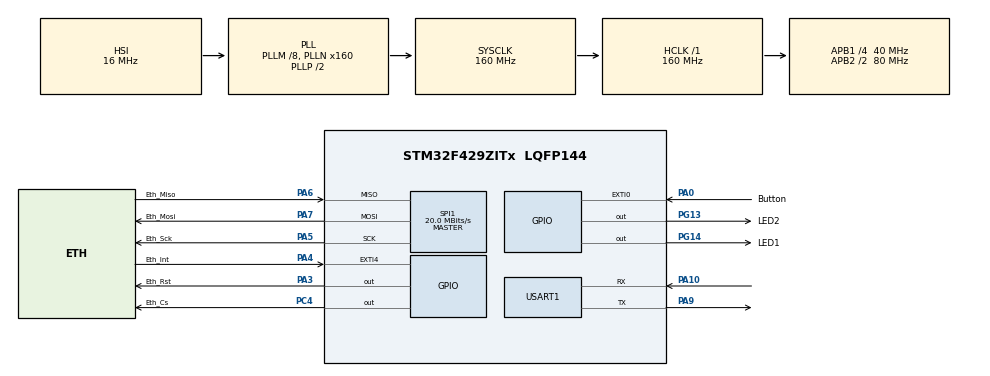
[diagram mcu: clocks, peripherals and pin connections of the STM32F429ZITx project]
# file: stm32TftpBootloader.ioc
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Mcu.Family=STM32F4
Mcu.Name=STM32F429ZITx
Mcu.Package=LQFP144
NVIC.EXTI0_IRQn=true\:0\:0\:false\:false\:true\:true\:true
NVIC.EXTI4_IRQn=true\:0\:0\:false\:false\:true\:true\:true
NVIC.PriorityGroup=NVIC_PRIORITYGROUP_4
NVIC.TIM1_TRG_COM_TIM11_IRQn=true\:0\:0\:false\:false\:true\:true\:true
NVIC.TIM1_UP_TIM10_IRQn=true\:0\:0\:false\:false\:true\:false\:true
NVIC.TimeBase=TIM1_UP_TIM10_IRQn
NVIC.TimeBaseIP=TIM1
PA0/WKUP.GPIO_Label=Button
PA0/WKUP.Signal=GPXTI0
PA10.Mode=Asynchronous
PA10.Signal=USART1_RX
PA3.GPIO_Label=Eth_Rst
PA3.Signal=GPIO_Output
PA4.GPIO_Label=Eth_Int
PA4.Signal=GPXTI4
PA5.GPIO_Label=Eth_Sck
PA5.Mode=Full_Duplex_Master
PA5.Signal=SPI1_SCK
PA6.GPIO_Label=Eth_Miso
PA6.Mode=Full_Duplex_Master
PA6.Signal=SPI1_MISO
PA7.GPIO_Label=Eth_Mosi
PA7.Mode=Full_Duplex_Master
PA7.Signal=SPI1_MOSI
PA9.Mode=Asynchronous
PA9.Signal=USART1_TX
PC4.GPIO_Label=Eth_Cs
PC4.Signal=GPIO_Output
PG13.GPIO_Label=LED2
PG13.Signal=GPIO_Output
PG14.GPIO_Label=LED1
PG14.Signal=GPIO_Output
PH0/OSC_IN.Mode=HSE-External-Oscillator
PH0/OSC_IN.Signal=RCC_OSC_IN
PH1/OSC_OUT.Mode=HSE-External-Oscillator
PH1/OSC_OUT.Signal=RCC_OSC_OUT
ProjectManager.HeapSize=0x200
ProjectManager.StackSize=0x400
ProjectManager.TargetToolchain=MDK-ARM V5
RCC.48MHZClocksFreq_Value=80000000
RCC.AHBFreq_Value=160000000
RCC.APB1CLKDivider=RCC_HCLK_DIV4
RCC.APB1Freq_Value=40000000
RCC.APB1TimFreq_Value=80000000
RCC.APB2CLKDivider=RCC_HCLK_DIV2
RCC.APB2Freq_Value=80000000
RCC.APB2TimFreq_Value=160000000
RCC.CortexFreq_Value=160000000
RCC.HCLKFreq_Value=160000000
RCC.HSE_VALUE=25000000
RCC.HSI_VALUE=16000000
RCC.LSE_VALUE=32768
RCC.PLLM=8
RCC.PLLN=160
RCC.SYSCLKFreq_VALUE=160000000
RCC.SYSCLKSource=RCC_SYSCLKSOURCE_PLLCLK
RCC.VCOOutputFreq_Value=320000000
SPI1.BaudRatePrescaler=SPI_BAUDRATEPRESCALER_4
SPI1.CalculateBaudRate=20.0 MBits/s
SPI1.Direction=SPI_DIRECTION_2LINES
SPI1.Mode=SPI_MODE_MASTER
SPI1.VirtualType=VM_MASTER
USART1.VirtualMode=VM_ASYNC
VP_SYS_VS_tim1.Mode=TIM1
VP_TIM11_VS_ClockSourceINT.Mode=Enable_Timer
board=custom

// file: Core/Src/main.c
/* USER CODE BEGIN Header */
/**
  ******************************************************************************
  * @file           : main.c
  * @brief          : Main program body
  ******************************************************************************
  * @attention
  *
  * <h2><center>&copy; Copyright (c) 2019 STMicroelectronics.
  * All rights reserved.</center></h2>
  *
  * This software component is licensed by ST under BSD 3-Clause license,
  * the "License"; You may not use this file except in compliance with the
  * License. You may obtain a copy of the License at:
  *                        opensource.org/licenses/BSD-3-Clause
  *
  ******************************************************************************
  */
/* USER CODE END Header */

#include "main.h"

/* USER CODE BEGIN Includes */
#include <systemControlCallback.h>
#include <etherflash.h>
#include <flash_if.h>

/* USER CODE END Includes */

SPI_HandleTypeDef hspi1;

TIM_HandleTypeDef htim11;

UART_HandleTypeDef huart1;

void SystemClock_Config(void);
static void MX_GPIO_Init(void);
static void MX_SPI1_Init(void);
static void MX_TIM11_Init(void);
static void MX_USART1_UART_Init(void);

/* USER CODE BEGIN 0 */
#define FILE_SIZE_LENGTH        ((uint32_t)16)
uint32_t flashdestination,ramsource;
uint8_t aPacketData[FILE_SIZE_LENGTH]={0,1,2,3,4,5,6,7,8,9,10,11,12,13,14,15};
/* USER CODE END 0 */

int main(void)
{

  /* MCU Configuration--------------------------------------------------------*/

  /* Reset of all peripherals, Initializes the Flash interface and the Systick. */
  HAL_Init();

  /* Configure the system clock */
  SystemClock_Config();

  /* Initialize all configured peripherals */
  MX_GPIO_Init();
  MX_SPI1_Init();
  MX_TIM11_Init();
  MX_USART1_UART_Init();
  /* USER CODE BEGIN 2 */
	pSystemControlCallbackStart();
	etherflash_main();
  /* USER CODE END 2 */

  /* Infinite loop */
  while (1)
  {

  }
}

void SystemClock_Config(void)
{
  RCC_OscInitTypeDef RCC_OscInitStruct = {0};
  RCC_ClkInitTypeDef RCC_ClkInitStruct = {0};

  /** Configure the main internal regulator output voltage
  */
  __HAL_RCC_PWR_CLK_ENABLE();
  __HAL_PWR_VOLTAGESCALING_CONFIG(PWR_REGULATOR_VOLTAGE_SCALE1);
  /** Initializes the CPU, AHB and APB busses clocks
  */
  RCC_OscInitStruct.OscillatorType = RCC_OSCILLATORTYPE_HSI;
  RCC_OscInitStruct.HSIState = RCC_HSI_ON;
  RCC_OscInitStruct.HSICalibrationValue = RCC_HSICALIBRATION_DEFAULT;
  RCC_OscInitStruct.PLL.PLLState = RCC_PLL_ON;
  RCC_OscInitStruct.PLL.PLLSource = RCC_PLLSOURCE_HSI;
  RCC_OscInitStruct.PLL.PLLM = 8;
  RCC_OscInitStruct.PLL.PLLN = 160;
  RCC_OscInitStruct.PLL.PLLP = RCC_PLLP_DIV2;
  RCC_OscInitStruct.PLL.PLLQ = 4;
  if (HAL_RCC_OscConfig(&RCC_OscInitStruct) != HAL_OK)
  {
    Error_Handler();
  }
  /** Initializes the CPU, AHB and APB busses clocks
  */
  RCC_ClkInitStruct.ClockType = RCC_CLOCKTYPE_HCLK|RCC_CLOCKTYPE_SYSCLK
                              |RCC_CLOCKTYPE_PCLK1|RCC_CLOCKTYPE_PCLK2;
  RCC_ClkInitStruct.SYSCLKSource = RCC_SYSCLKSOURCE_PLLCLK;
  RCC_ClkInitStruct.AHBCLKDivider = RCC_SYSCLK_DIV1;
  RCC_ClkInitStruct.APB1CLKDivider = RCC_HCLK_DIV4;
  RCC_ClkInitStruct.APB2CLKDivider = RCC_HCLK_DIV2;

  if (HAL_RCC_ClockConfig(&RCC_ClkInitStruct, FLASH_LATENCY_5) != HAL_OK)
  {
    Error_Handler();
  }
}

static void MX_SPI1_Init(void)
{

  /* SPI1 parameter configuration*/
  hspi1.Instance = SPI1;
  hspi1.Init.Mode = SPI_MODE_MASTER;
  hspi1.Init.Direction = SPI_DIRECTION_2LINES;
  hspi1.Init.DataSize = SPI_DATASIZE_8BIT;
  hspi1.Init.CLKPolarity = SPI_POLARITY_LOW;
  hspi1.Init.CLKPhase = SPI_PHASE_1EDGE;
  hspi1.Init.NSS = SPI_NSS_SOFT;
  hspi1.Init.BaudRatePrescaler = SPI_BAUDRATEPRESCALER_4;
  hspi1.Init.FirstBit = SPI_FIRSTBIT_MSB;
  hspi1.Init.TIMode = SPI_TIMODE_DISABLE;
  hspi1.Init.CRCCalculation = SPI_CRCCALCULATION_DISABLE;
  hspi1.Init.CRCPolynomial = 10;
  if (HAL_SPI_Init(&hspi1) != HAL_OK)
  {
    Error_Handler();
  }

}

static void MX_TIM11_Init(void)
{

  htim11.Instance = TIM11;
  htim11.Init.Prescaler = (1600 - 1);
  htim11.Init.CounterMode = TIM_COUNTERMODE_UP;
  htim11.Init.Period = (100000 - 1);
  htim11.Init.ClockDivision = TIM_CLOCKDIVISION_DIV1;
  htim11.Init.AutoReloadPreload = TIM_AUTORELOAD_PRELOAD_DISABLE;
  if (HAL_TIM_Base_Init(&htim11) != HAL_OK)
  {
    Error_Handler();
  }

}

static void MX_USART1_UART_Init(void)
{

  huart1.Instance = USART1;
  huart1.Init.BaudRate = 115200;
  huart1.Init.WordLength = UART_WORDLENGTH_8B;
  huart1.Init.StopBits = UART_STOPBITS_1;
  huart1.Init.Parity = UART_PARITY_NONE;
  huart1.Init.Mode = UART_MODE_TX_RX;
  huart1.Init.HwFlowCtl = UART_HWCONTROL_NONE;
  huart1.Init.OverSampling = UART_OVERSAMPLING_16;
  if (HAL_UART_Init(&huart1) != HAL_OK)
  {
    Error_Handler();
  }

}

static void MX_GPIO_Init(void)
{
  GPIO_InitTypeDef GPIO_InitStruct = {0};

  /* GPIO Ports Clock Enable */
  __HAL_RCC_GPIOH_CLK_ENABLE();
  __HAL_RCC_GPIOA_CLK_ENABLE();
  __HAL_RCC_GPIOC_CLK_ENABLE();
  __HAL_RCC_GPIOG_CLK_ENABLE();

  /*Configure GPIO pin Output Level */
  HAL_GPIO_WritePin(Eth_Rst_GPIO_Port, Eth_Rst_Pin, GPIO_PIN_RESET);

  /*Configure GPIO pin Output Level */
  HAL_GPIO_WritePin(Eth_Cs_GPIO_Port, Eth_Cs_Pin, GPIO_PIN_RESET);

  /*Configure GPIO pin Output Level */
  HAL_GPIO_WritePin(GPIOG, LED2_Pin|LED1_Pin, GPIO_PIN_RESET);

  /*Configure GPIO pins : Button_Pin Eth_Int_Pin */
  GPIO_InitStruct.Pin = Button_Pin|Eth_Int_Pin;
  GPIO_InitStruct.Mode = GPIO_MODE_IT_RISING;
  GPIO_InitStruct.Pull = GPIO_NOPULL;
  HAL_GPIO_Init(GPIOA, &GPIO_InitStruct);

  /*Configure GPIO pin : Eth_Rst_Pin */
  GPIO_InitStruct.Pin = Eth_Rst_Pin;
  GPIO_InitStruct.Mode = GPIO_MODE_OUTPUT_PP;
  GPIO_InitStruct.Pull = GPIO_NOPULL;
  GPIO_InitStruct.Speed = GPIO_SPEED_FREQ_LOW;
  HAL_GPIO_Init(Eth_Rst_GPIO_Port, &GPIO_InitStruct);

  /*Configure GPIO pin : Eth_Cs_Pin */
  GPIO_InitStruct.Pin = Eth_Cs_Pin;
  GPIO_InitStruct.Mode = GPIO_MODE_OUTPUT_PP;
  GPIO_InitStruct.Pull = GPIO_NOPULL;
  GPIO_InitStruct.Speed = GPIO_SPEED_FREQ_LOW;
  HAL_GPIO_Init(Eth_Cs_GPIO_Port, &GPIO_InitStruct);

  /*Configure GPIO pins : LED2_Pin LED1_Pin */
  GPIO_InitStruct.Pin = LED2_Pin|LED1_Pin;
  GPIO_InitStruct.Mode = GPIO_MODE_OUTPUT_PP;
  GPIO_InitStruct.Pull = GPIO_NOPULL;
  GPIO_InitStruct.Speed = GPIO_SPEED_FREQ_LOW;
  HAL_GPIO_Init(GPIOG, &GPIO_InitStruct);

  /* EXTI interrupt init*/
  HAL_NVIC_SetPriority(EXTI0_IRQn, 0, 0);
  HAL_NVIC_EnableIRQ(EXTI0_IRQn);

  HAL_NVIC_SetPriority(EXTI4_IRQn, 0, 0);
  HAL_NVIC_EnableIRQ(EXTI4_IRQn);

}

void HAL_TIM_PeriodElapsedCallback(TIM_HandleTypeDef *htim)
{
  if (htim->Instance == TIM1) {
    HAL_IncTick();
  }
	else if (htim->Instance == TIM11) //check if the interrupt comes from TIM3
	{
		pSystemControlCallback();
	}
}

void Error_Handler(void)
{
}

/************************ (C) COPYRIGHT STMicroelectronics *****END OF FILE****/
